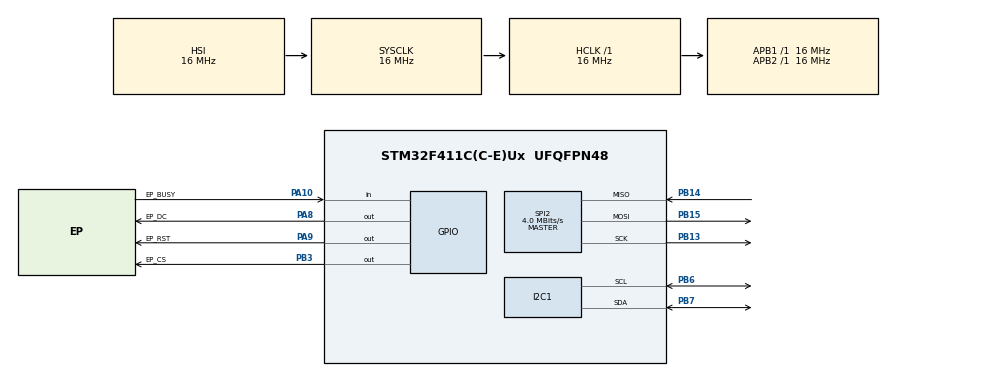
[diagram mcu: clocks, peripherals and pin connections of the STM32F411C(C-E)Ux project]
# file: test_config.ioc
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Mcu.Family=STM32F4
Mcu.Name=STM32F411C(C-E)Ux
Mcu.Package=UFQFPN48
NVIC.PriorityGroup=NVIC_PRIORITYGROUP_4
PA10.GPIO_Label=EP_BUSY
PA10.Signal=GPIO_Input
PA8.GPIO_Label=EP_DC
PA8.Signal=GPIO_Output
PA9.GPIO_Label=EP_RST
PA9.PinState=GPIO_PIN_SET
PA9.Signal=GPIO_Output
PB13.Mode=Full_Duplex_Master
PB13.Signal=SPI2_SCK
PB14.Mode=Full_Duplex_Master
PB14.Signal=SPI2_MISO
PB15.Mode=Full_Duplex_Master
PB15.Signal=SPI2_MOSI
PB3.GPIO_Label=EP_CS
PB3.PinState=GPIO_PIN_SET
PB3.Signal=GPIO_Output
PB6.Mode=I2C
PB6.Signal=I2C1_SCL
PB7.Mode=I2C
PB7.Signal=I2C1_SDA
ProjectManager.HeapSize=0x200
ProjectManager.StackSize=0x400
ProjectManager.TargetToolchain=CMake
RCC.AHBFreq_Value=16000000
RCC.APB1Freq_Value=16000000
RCC.APB2Freq_Value=16000000
RCC.CortexFreq_Value=16000000
RCC.HSE_VALUE=25000000
RCC.HSI_VALUE=16000000
RCC.LSE_VALUE=32768
RCC.SYSCLKFreq_VALUE=16000000
RCC.VCOOutputFreq_Value=192000000
SPI2.BaudRatePrescaler=SPI_BAUDRATEPRESCALER_4
SPI2.CalculateBaudRate=4.0 MBits/s
SPI2.Direction=SPI_DIRECTION_2LINES
SPI2.Mode=SPI_MODE_MASTER
SPI2.VirtualType=VM_MASTER
board=custom

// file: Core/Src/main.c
/* USER CODE BEGIN Header */
/**
  ******************************************************************************
  * @file           : main.c
  * @brief          : Main program body
  ******************************************************************************
  * @attention
  *
  * Copyright (c) 2026 STMicroelectronics.
  * All rights reserved.
  *
  * This software is licensed under terms that can be found in the LICENSE file
  * in the root directory of this software component.
  * If no LICENSE file comes with this software, it is provided AS-IS.
  *
  ******************************************************************************
  */
/* USER CODE END Header */
#include "main.h"

/* USER CODE BEGIN Includes */
#include "epaper.h"
#include "ina219.h"
#include "bme280.h"
#include <stdio.h>
/* USER CODE END Includes */

I2C_HandleTypeDef hi2c1;

SPI_HandleTypeDef hspi2;

void SystemClock_Config(void);
static void MX_GPIO_Init(void);
static void MX_SPI2_Init(void);
static void MX_I2C1_Init(void);

int main(void)
{

  /* MCU Configuration--------------------------------------------------------*/

  /* Reset of all peripherals, Initializes the Flash interface and the Systick. */
  HAL_Init();

  /* Configure the system clock */
  SystemClock_Config();

  /* Initialize all configured peripherals */
  MX_GPIO_Init();
  MX_SPI2_Init();
  MX_I2C1_Init();
  /* USER CODE BEGIN 2 */

    HAL_StatusTypeDef ina_status = INA219_Init(&hi2c1);
    HAL_StatusTypeDef bme_status = BME280_Init(&hi2c1);

    EPD_Init();

    EPD_ClearBuffer();

    EPD_DrawString(10, 20, "TEST", &Font8, EPD_BLACK);

    EPD_Display();
  /* USER CODE END 2 */

  /* Infinite loop */
    while (1)
    {

    /* USER CODE BEGIN 3 */

        /*BME280_Data weather;

        if (BME280_Read(&weather) == HAL_OK)
        {
            char line[32];

            float temp_f =
                (weather.temperature_c * 9.0f / 5.0f) + 32.0f;

            EPD_ClearBuffer();

            snprintf(line, sizeof(line),
                     "Temp: %.1f F", temp_f);

            EPD_DrawString(10, 20, line,
                           &Font8, EPD_BLACK);

            snprintf(line, sizeof(line),
                     "Humidity: %.1f%%", weather.humidity);

            EPD_DrawString(10, 40, line,
                           &Font8, EPD_BLACK);

            snprintf(line, sizeof(line),
                     "Pressure: %.1f hPa", weather.pressure_hpa);

            EPD_DrawString(10, 60, line,
                           &Font8, EPD_BLACK);

            EPD_Display();
        }

        HAL_Delay(300000); */  // 5 minutes

    }
  /* USER CODE END 3 */
}

void SystemClock_Config(void)
{
  RCC_OscInitTypeDef RCC_OscInitStruct = {0};
  RCC_ClkInitTypeDef RCC_ClkInitStruct = {0};

  /** Configure the main internal regulator output voltage
  */
  __HAL_RCC_PWR_CLK_ENABLE();
  __HAL_PWR_VOLTAGESCALING_CONFIG(PWR_REGULATOR_VOLTAGE_SCALE1);

  /** Initializes the RCC Oscillators according to the specified parameters
  * in the RCC_OscInitTypeDef structure.
  */
  RCC_OscInitStruct.OscillatorType = RCC_OSCILLATORTYPE_HSI;
  RCC_OscInitStruct.HSIState = RCC_HSI_ON;
  RCC_OscInitStruct.HSICalibrationValue = RCC_HSICALIBRATION_DEFAULT;
  RCC_OscInitStruct.PLL.PLLState = RCC_PLL_NONE;
  if (HAL_RCC_OscConfig(&RCC_OscInitStruct) != HAL_OK)
  {
    Error_Handler();
  }

  /** Initializes the CPU, AHB and APB buses clocks
  */
  RCC_ClkInitStruct.ClockType = RCC_CLOCKTYPE_HCLK|RCC_CLOCKTYPE_SYSCLK
                              |RCC_CLOCKTYPE_PCLK1|RCC_CLOCKTYPE_PCLK2;
  RCC_ClkInitStruct.SYSCLKSource = RCC_SYSCLKSOURCE_HSI;
  RCC_ClkInitStruct.AHBCLKDivider = RCC_SYSCLK_DIV1;
  RCC_ClkInitStruct.APB1CLKDivider = RCC_HCLK_DIV1;
  RCC_ClkInitStruct.APB2CLKDivider = RCC_HCLK_DIV1;

  if (HAL_RCC_ClockConfig(&RCC_ClkInitStruct, FLASH_LATENCY_0) != HAL_OK)
  {
    Error_Handler();
  }
}

static void MX_I2C1_Init(void)
{

  hi2c1.Instance = I2C1;
  hi2c1.Init.ClockSpeed = 100000;
  hi2c1.Init.DutyCycle = I2C_DUTYCYCLE_2;
  hi2c1.Init.OwnAddress1 = 0;
  hi2c1.Init.AddressingMode = I2C_ADDRESSINGMODE_7BIT;
  hi2c1.Init.DualAddressMode = I2C_DUALADDRESS_DISABLE;
  hi2c1.Init.OwnAddress2 = 0;
  hi2c1.Init.GeneralCallMode = I2C_GENERALCALL_DISABLE;
  hi2c1.Init.NoStretchMode = I2C_NOSTRETCH_DISABLE;
  if (HAL_I2C_Init(&hi2c1) != HAL_OK)
  {
    Error_Handler();
  }

}

static void MX_SPI2_Init(void)
{

  /* SPI2 parameter configuration*/
  hspi2.Instance = SPI2;
  hspi2.Init.Mode = SPI_MODE_MASTER;
  hspi2.Init.Direction = SPI_DIRECTION_2LINES;
  hspi2.Init.DataSize = SPI_DATASIZE_8BIT;
  hspi2.Init.CLKPolarity = SPI_POLARITY_LOW;
  hspi2.Init.CLKPhase = SPI_PHASE_1EDGE;
  hspi2.Init.NSS = SPI_NSS_SOFT;
  hspi2.Init.BaudRatePrescaler = SPI_BAUDRATEPRESCALER_4;
  hspi2.Init.FirstBit = SPI_FIRSTBIT_MSB;
  hspi2.Init.TIMode = SPI_TIMODE_DISABLE;
  hspi2.Init.CRCCalculation = SPI_CRCCALCULATION_DISABLE;
  hspi2.Init.CRCPolynomial = 10;
  if (HAL_SPI_Init(&hspi2) != HAL_OK)
  {
    Error_Handler();
  }

}

static void MX_GPIO_Init(void)
{
  GPIO_InitTypeDef GPIO_InitStruct = {0};

  /* GPIO Ports Clock Enable */
  __HAL_RCC_GPIOB_CLK_ENABLE();
  __HAL_RCC_GPIOA_CLK_ENABLE();

  /*Configure GPIO pin Output Level */
  HAL_GPIO_WritePin(EP_DC_GPIO_Port, EP_DC_Pin, GPIO_PIN_RESET);

  /*Configure GPIO pin Output Level */
  HAL_GPIO_WritePin(EP_RST_GPIO_Port, EP_RST_Pin, GPIO_PIN_SET);

  /*Configure GPIO pin Output Level */
  HAL_GPIO_WritePin(EP_CS_GPIO_Port, EP_CS_Pin, GPIO_PIN_SET);

  /*Configure GPIO pins : EP_DC_Pin EP_RST_Pin */
  GPIO_InitStruct.Pin = EP_DC_Pin|EP_RST_Pin;
  GPIO_InitStruct.Mode = GPIO_MODE_OUTPUT_PP;
  GPIO_InitStruct.Pull = GPIO_NOPULL;
  GPIO_InitStruct.Speed = GPIO_SPEED_FREQ_LOW;
  HAL_GPIO_Init(GPIOA, &GPIO_InitStruct);

  /*Configure GPIO pin : EP_BUSY_Pin */
  GPIO_InitStruct.Pin = EP_BUSY_Pin;
  GPIO_InitStruct.Mode = GPIO_MODE_INPUT;
  GPIO_InitStruct.Pull = GPIO_NOPULL;
  HAL_GPIO_Init(EP_BUSY_GPIO_Port, &GPIO_InitStruct);

  /*Configure GPIO pin : EP_CS_Pin */
  GPIO_InitStruct.Pin = EP_CS_Pin;
  GPIO_InitStruct.Mode = GPIO_MODE_OUTPUT_PP;
  GPIO_InitStruct.Pull = GPIO_NOPULL;
  GPIO_InitStruct.Speed = GPIO_SPEED_FREQ_LOW;
  HAL_GPIO_Init(EP_CS_GPIO_Port, &GPIO_InitStruct);

}

void Error_Handler(void)
{
  __disable_irq();
  while (1)
  {
  }
}
